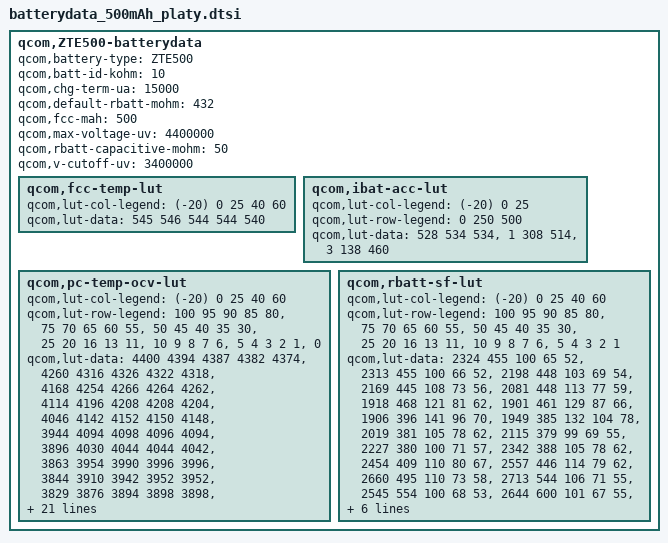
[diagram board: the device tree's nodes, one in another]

qcom,ZTE500-batterydata {
	qcom,battery-type = "ZTE500";
	qcom,batt-id-kohm = <10>;
	qcom,chg-term-ua = <15000>;
	qcom,default-rbatt-mohm = <432>;
	qcom,fcc-mah = <500>;
	qcom,max-voltage-uv = <4400000>;
	qcom,rbatt-capacitive-mohm = <50>;
	qcom,v-cutoff-uv = <3400000>;

	qcom,fcc-temp-lut {
		qcom,lut-col-legend = <(-20) 0 25 40 60>;
		qcom,lut-data = <545 546 544 544 540>;
	};

	qcom,ibat-acc-lut {
		qcom,lut-col-legend = <(-20) 0 25>;
		qcom,lut-row-legend = <0 250 500>;
		qcom,lut-data = <528 534 534>,
				<1 308 514>,
				<3 138 460>;
	};

	qcom,pc-temp-ocv-lut {
		qcom,lut-col-legend = <(-20) 0 25 40 60>;
		qcom,lut-row-legend = <100 95 90 85 80>,
					<75 70 65 60 55>,
					<50 45 40 35 30>,
					<25 20 16 13 11>,
					<10 9 8 7 6>,
					<5 4 3 2 1>,
					<0>;
		qcom,lut-data = <4400 4394 4387 4382 4374>,
				<4260 4316 4326 4322 4318>,
				<4168 4254 4266 4264 4262>,
				<4114 4196 4208 4208 4204>,
				<4046 4142 4152 4150 4148>,
				<3944 4094 4098 4096 4094>,
				<3896 4030 4044 4044 4042>,
				<3863 3954 3990 3996 3996>,
				<3844 3910 3942 3952 3952>,
				<3829 3876 3894 3898 3898>,
				<3815 3844 3858 3860 3860>,
				<3801 3816 3831 3832 3832>,
				<3786 3796 3809 3810 3810>,
				<3769 3782 3790 3790 3790>,
				<3751 3770 3775 3772 3766>,
				<3732 3755 3759 3752 3739>,
				<3711 3733 3736 3728 3712>,
				<3691 3710 3700 3692 3678>,
				<3669 3699 3690 3682 3671>,
				<3653 3694 3688 3681 3669>,
				<3642 3691 3687 3680 3668>,
				<3628 3688 3685 3678 3665>,
				<3613 3684 3681 3674 3657>,
				<3589 3672 3666 3658 3636>,
				<3560 3646 3634 3626 3604>,
				<3520 3604 3594 3587 3567>,
				<3462 3550 3548 3542 3520>,
				<3387 3486 3488 3481 3458>,
				<3295 3404 3404 3394 3365>,
				<3212 3286 3274 3262 3230>,
				<3019 3000 3000 3000 3000>;
	};

	qcom,rbatt-sf-lut {
		qcom,lut-col-legend = <(-20) 0 25 40 60>;
		qcom,lut-row-legend = <100 95 90 85 80>,
					<75 70 65 60 55>,
					<50 45 40 35 30>,
					<25 20 16 13 11>,
					<10 9 8 7 6>,
					<5 4 3 2 1>;
		qcom,lut-data = <2324 455 100 65 52>,
				<2313 455 100 66 52>,
				<2198 448 103 69 54>,
				<2169 445 108 73 56>,
				<2081 448 113 77 59>,
				<1918 468 121 81 62>,
				<1901 461 129 87 66>,
				<1906 396 141 96 70>,
				<1949 385 132 104 78>,
				<2019 381 105 78 62>,
				<2115 379 99 69 55>,
				<2227 380 100 71 57>,
				<2342 388 105 78 62>,
				<2454 409 110 80 67>,
				<2557 446 114 79 62>,
				<2660 495 110 73 58>,
				<2713 544 106 71 55>,
				<2545 554 100 68 53>,
				<2644 600 101 67 55>,
				<2741 647 111 75 58>,
				<2894 674 118 78 60>,
				<3123 706 123 80 60>,
				<3397 738 130 82 59>,
				<3742 764 128 79 62>,
				<4220 788 129 84 76>,
				<4878 822 147 105 91>,
				<5859 876 169 118 93>,
				<7679 964 182 122 96>,
				<12855 1076 198 136 109>,
				<25709 1337 272 204 174>;
	};
};
/* TEST_DB_ID=TEST_ID_NOT_SET */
